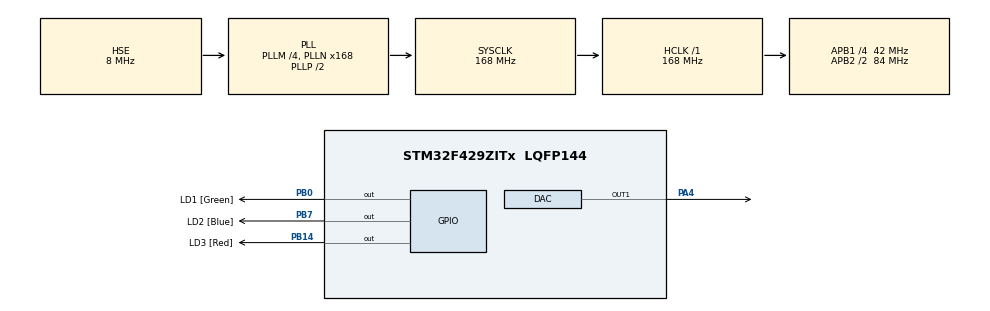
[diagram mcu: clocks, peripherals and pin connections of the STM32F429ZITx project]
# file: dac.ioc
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Mcu.Family=STM32F4
Mcu.Name=STM32F429ZITx
Mcu.Package=LQFP144
NVIC.PriorityGroup=NVIC_PRIORITYGROUP_4
PA4.Signal=COMP_DAC1_group
PB0.GPIO_Label=LD1 [Green]
PB0.Signal=GPIO_Output
PB14.GPIO_Label=LD3 [Red]
PB14.Signal=GPIO_Output
PB7.GPIO_Label=LD2 [Blue]
PB7.Signal=GPIO_Output
PH0/OSC_IN.Mode=HSE-External-Clock-Source
PH0/OSC_IN.Signal=RCC_OSC_IN
PH1/OSC_OUT.Mode=HSE-External-Clock-Source
PH1/OSC_OUT.Signal=RCC_OSC_OUT
ProjectManager.HeapSize=0x200
ProjectManager.StackSize=0x400
ProjectManager.TargetToolchain=Makefile
RCC.48MHZClocksFreq_Value=48000000
RCC.AHBFreq_Value=168000000
RCC.APB1CLKDivider=RCC_HCLK_DIV4
RCC.APB1Freq_Value=42000000
RCC.APB1TimFreq_Value=84000000
RCC.APB2CLKDivider=RCC_HCLK_DIV2
RCC.APB2Freq_Value=84000000
RCC.APB2TimCLKDivider=2
RCC.APB2TimFreq_Value=168000000
RCC.CortexFreq_Value=168000000
RCC.HCLKFreq_Value=168000000
RCC.HSE_VALUE=8000000
RCC.HSI_VALUE=16000000
RCC.PLLM=4
RCC.PLLMUL=RCC_PLL_MUL9
RCC.PLLN=168
RCC.PLLQ=7
RCC.PLLSourceVirtual=RCC_PLLSOURCE_HSE
RCC.PRESCALERUSB=RCC_USBCLKSOURCE_PLL_DIV1_5
RCC.SYSCLKFreq_VALUE=168000000
RCC.SYSCLKSource=RCC_SYSCLKSOURCE_PLLCLK
RCC.SYSCLKSourceVirtual=RCC_SYSCLKSOURCE_PLLCLK
RCC.USBFreq_Value=48000000
RCC.VCOOutputFreq_Value=336000000
SH.COMP_DAC1_group.0=DAC_OUT1,DAC_OUT1
board=NUCLEO-F429ZI

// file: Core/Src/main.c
/* USER CODE BEGIN Header */
/**
  ******************************************************************************
  * @file           : main.c
  * @brief          : Main program body
  ******************************************************************************
  * @attention
  *
  * <h2><center>&copy; Copyright (c) 2022 STMicroelectronics.
  * All rights reserved.</center></h2>
  *
  * This software component is licensed by ST under BSD 3-Clause license,
  * the "License"; You may not use this file except in compliance with the
  * License. You may obtain a copy of the License at:
  *                        opensource.org/licenses/BSD-3-Clause
  *
  ******************************************************************************
  */
/* USER CODE END Header */
#include "main.h"
#include "dac.h"
#include "gpio.h"

void SystemClock_Config(void);

int main(void)
{

  /* MCU Configuration--------------------------------------------------------*/

  /* Reset of all peripherals, Initializes the Flash interface and the Systick. */
  HAL_Init();

  /* Configure the system clock */
  SystemClock_Config();

  /* Initialize all configured peripherals */
  MX_GPIO_Init();
  MX_DAC_Init();
  /* USER CODE BEGIN 2 */
  if (HAL_DAC_SetValue(&hdac, DAC_CHANNEL_1, DAC_ALIGN_12B_R, 2048) != HAL_OK)
    Error_Handler();

	if (HAL_DAC_Start(&hdac,DAC_CHANNEL_1) != HAL_OK)
    Error_Handler();

  if (HAL_DAC_Stop(&hdac,DAC_CHANNEL_1) != HAL_OK)
    Error_Handler();
  /* USER CODE END 2 */

  /* Infinite loop */
  /* USER CODE BEGIN WHILE */
  while (1)
  {
    HAL_GPIO_TogglePin(LD1_GPIO_Port, LD1_Pin);
    HAL_GPIO_TogglePin(LD2_GPIO_Port, LD2_Pin);
    HAL_GPIO_TogglePin(LD3_GPIO_Port, LD3_Pin);
    /* USER CODE END WHILE */

    /* USER CODE BEGIN 3 */
    HAL_Delay(500);
  }
  /* USER CODE END 3 */
}

void SystemClock_Config(void)
{
  RCC_OscInitTypeDef RCC_OscInitStruct = {0};
  RCC_ClkInitTypeDef RCC_ClkInitStruct = {0};

  /** Configure the main internal regulator output voltage
  */
  __HAL_RCC_PWR_CLK_ENABLE();
  __HAL_PWR_VOLTAGESCALING_CONFIG(PWR_REGULATOR_VOLTAGE_SCALE1);
  /** Initializes the RCC Oscillators according to the specified parameters
  * in the RCC_OscInitTypeDef structure.
  */
  RCC_OscInitStruct.OscillatorType = RCC_OSCILLATORTYPE_HSE;
  RCC_OscInitStruct.HSEState = RCC_HSE_BYPASS;
  RCC_OscInitStruct.PLL.PLLState = RCC_PLL_ON;
  RCC_OscInitStruct.PLL.PLLSource = RCC_PLLSOURCE_HSE;
  RCC_OscInitStruct.PLL.PLLM = 4;
  RCC_OscInitStruct.PLL.PLLN = 168;
  RCC_OscInitStruct.PLL.PLLP = RCC_PLLP_DIV2;
  RCC_OscInitStruct.PLL.PLLQ = 7;
  if (HAL_RCC_OscConfig(&RCC_OscInitStruct) != HAL_OK)
  {
    Error_Handler();
  }
  /** Initializes the CPU, AHB and APB buses clocks
  */
  RCC_ClkInitStruct.ClockType = RCC_CLOCKTYPE_HCLK|RCC_CLOCKTYPE_SYSCLK
                              |RCC_CLOCKTYPE_PCLK1|RCC_CLOCKTYPE_PCLK2;
  RCC_ClkInitStruct.SYSCLKSource = RCC_SYSCLKSOURCE_PLLCLK;
  RCC_ClkInitStruct.AHBCLKDivider = RCC_SYSCLK_DIV1;
  RCC_ClkInitStruct.APB1CLKDivider = RCC_HCLK_DIV4;
  RCC_ClkInitStruct.APB2CLKDivider = RCC_HCLK_DIV2;

  if (HAL_RCC_ClockConfig(&RCC_ClkInitStruct, FLASH_LATENCY_5) != HAL_OK)
  {
    Error_Handler();
  }
}

void Error_Handler(void)
{
  __disable_irq();
  while (1)
  {
  }
}

/************************ (C) COPYRIGHT STMicroelectronics *****END OF FILE****/
